# ECAP0_CTL_STS register map
Vendor: Texas Instruments
Peripheral module from a debugger description file (folder J7VCL).
Registers are 32-bit, read-write, reset 0x0 unless marked. A register's access mark holds for its fields unless they carry their own. Offsets are as the file gives them; lines under a group give offsets from that group; [hi:lo] are bit positions; {n}, {i} and the like mark numbered series; 'fields as' and 'values as' point back to an identical list; <NAME> marks a mode.

## ECAP0_CTL_STS
0x00 ECAP_TSCNT — Time Stamp Counter register
  [31:0] TSCNT — Active 32-bit counter register which is used as the capture time-base.
0x04 ECAP_CNTPHS — Counter Phase Control register
  [31:0] CNTPHS — Counter phase value register that can be programmed for phase Lag/Lead.
0x08 ECAP_CAP1 — Capture-1 register
  [31:0] CAP1 — This register can be loaded (written) by:
0x0C ECAP_CAP2 — Capture-2 register
  [31:0] CAP2 — This register can be loaded (written) by:
0x10 ECAP_CAP3 — Capture-3 register
  [31:0] CAP3 — In CMP mode this is a time-stamp capture register. In APMW mode this is the period shadow (APER) register.
0x14 ECAP_CAP4 — Capture-4 register
  [31:0] CAP4 — In CMP mode this is a time-stamp capture register. In APMW mode this is the compare shadow (ACMP) register.
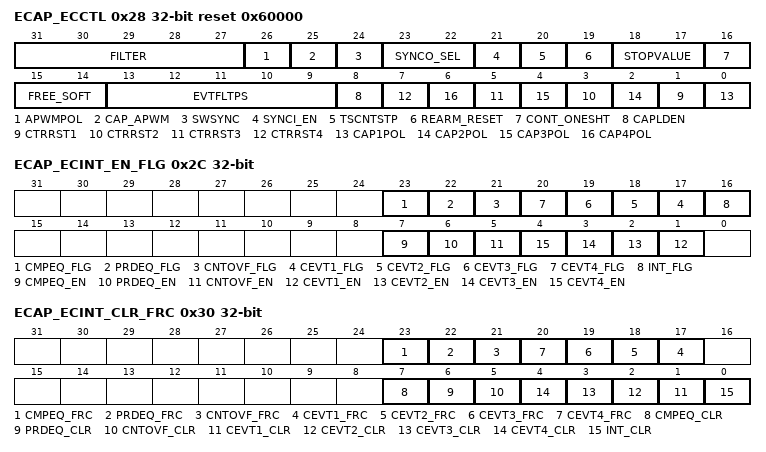
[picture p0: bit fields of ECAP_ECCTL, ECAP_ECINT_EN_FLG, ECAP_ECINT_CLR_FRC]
0x28 ECAP_ECCTL access not given reset 0x60000 — ECAP Control register
  [31:27] FILTER ro
  [26] APWMPOL rw — APWM Output Polarity Select:
  [25] CAP_APWM rw — CAP/APWM Operating Mode Select:
  [24] SWSYNC — Software Forced Counter ( (access WCap)
  [23:22] SYNCO_SEL rw — SyncOut Select:
  [21] SYNCI_EN rw — Counter (
  [20] TSCNTSTP rw — Counter Stop (freeze) Control:
  [19] REARM_RESET — One-Shot 'Re-arming' Control Write 0h = Has no effect. (access WCap)
  [18:17] STOPVALUE rw — Stop Value for One-Shot Mode:
  [16] CONT_ONESHT rw — Continuous or One-shot Mode Control (applicable only in Capture mode):
  [15:14] FREE_SOFT rw — Emulation Control
  [13:9] EVTFLTPS rw — Event Filter Prescale Select:
  [8] CAPLDEN rw — Enable Loading of the
  [2n-1] CTRRST{n} rw (n=1..4) — Counter Reset on Capture Event {n}:
  [2n-2] CAP{n}POL rw (n=1..4) — Capture Event {n} Polarity Select:
0x2C ECAP_ECINT_EN_FLG access per field — ECAP Interrupt Enable and Flag register
  [23] CMPEQ_FLG ro — Compare Equal Status Flag:
  [22] PRDEQ_FLG ro — Period Equal Status Flag:
  [21] CNTOVF_FLG ro — Counter Overflow Status Flag:
  [n+16] CEVT{n}_FLG ro (n=1..4) — Capture Event {n} Status Flag:
  [16] INT_FLG ro — Global Interrupt Status Flag:
  [7] CMPEQ_EN rw — Compare Equal Interrupt Enable:
  [6] PRDEQ_EN rw — Period Equal Interrupt Enable:
  [5] CNTOVF_EN rw — Counter Overflow Interrupt Enable:
  [n] CEVT{n}_EN rw (n=1..4) — Capture Event {n} Interrupt Enable:
0x30 ECAP_ECINT_CLR_FRC access not given — ECAP Interrupt Clear and Forcing register
  [23] CMPEQ_FRC — Force Compare Equal: (access W1S)
  [22] PRDEQ_FRC — Force Period Equal: (access W1S)
  [21] CNTOVF_FRC — Force Counter Overflow: (access W1S)
  [n+16] CEVT{n}_FRC (n=1..4) — Force Capture Event {n}: (access W1S)
  [7] CMPEQ_CLR — Compare Equal Status Flag: (access W1C)
  [6] PRDEQ_CLR — Period Equal Status Flag: (access W1C)
  [5] CNTOVF_CLR — Counter Overflow Status Flag: (access W1C)
  [n] CEVT{n}_CLR (n=1..4) — Capture Event {n} Status Flag: (access W1C)
  [0] INT_CLR — Global Interrupt Clear Flag: (access W1C)
0x5C ECAP_PID ro reset 0x44D24100 — Peripheral ID register
  [31:0] REVISION — TI internal data. Identifies revision of peripheral.
